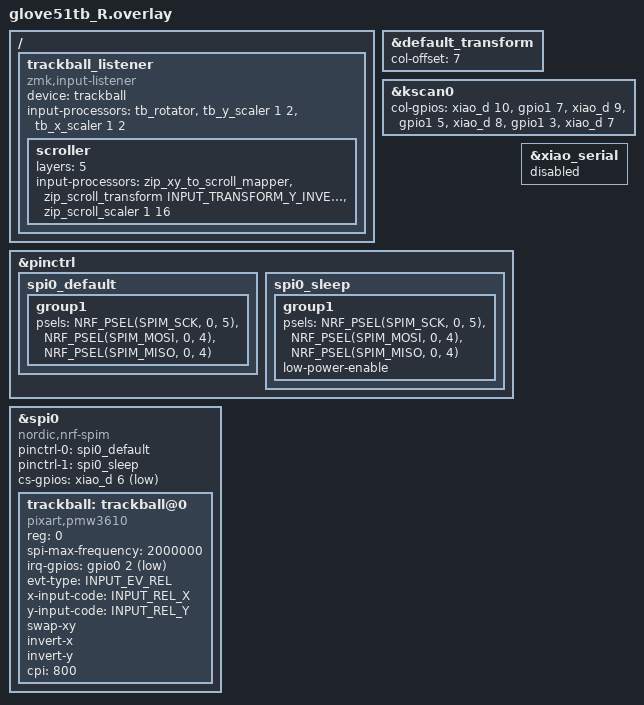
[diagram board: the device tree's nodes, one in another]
#include "glove51tb.dtsi"
#include <zephyr/dt-bindings/input/input-event-codes.h>
#include <dt-bindings/zmk/input_transform.h>
#include <input/processors.dtsi>

&default_transform {
    col-offset = <7>;
};

&kscan0 {
        col-gpios
            = <&xiao_d 10 GPIO_ACTIVE_HIGH>
            , <&gpio1 7  GPIO_ACTIVE_HIGH>
            , <&xiao_d 9  GPIO_ACTIVE_HIGH>
            , <&gpio1 5  GPIO_ACTIVE_HIGH>
            , <&xiao_d 8  GPIO_ACTIVE_HIGH>
            , <&gpio1 3  GPIO_ACTIVE_HIGH>
            , <&xiao_d 7  GPIO_ACTIVE_HIGH>
            ;
};

/ {
    trackball_listener {
        status = "okay";
        compatible = "zmk,input-listener";
        device = <&trackball>;
        input-processors = <&tb_rotator &tb_y_scaler 1 2 &tb_x_scaler 1 2>;

        scroller {
            layers = <5>;                                      // スクロールレイヤー
            input-processors = <
                &zip_xy_to_scroll_mapper                       // XY移動でスクロール
                &zip_scroll_transform INPUT_TRANSFORM_Y_INVERT // スクロールのY軸を反転
                &zip_scroll_scaler 1 16                        // スクロール感度調整
            >;
        };
    };
};

&pinctrl {
    spi0_default: spi0_default {
        group1 {
            psels = <NRF_PSEL(SPIM_SCK, 0, 5)>,
                <NRF_PSEL(SPIM_MOSI, 0, 4)>,
                <NRF_PSEL(SPIM_MISO, 0, 4)>;
        };
    };

    spi0_sleep: spi0_sleep {
        group1 {
            psels = <NRF_PSEL(SPIM_SCK, 0, 5)>,
                <NRF_PSEL(SPIM_MOSI, 0, 4)>,
                <NRF_PSEL(SPIM_MISO, 0, 4)>;
            low-power-enable;
        };
    };
};

&xiao_serial { status = "disabled"; };

&spi0 {
    status = "okay";
    compatible = "nordic,nrf-spim";
    pinctrl-0 = <&spi0_default>;
    pinctrl-1 = <&spi0_sleep>;
    pinctrl-names = "default", "sleep";
    cs-gpios = <&xiao_d 6 GPIO_ACTIVE_LOW>;

    trackball: trackball@0 {
        status = "okay";
        compatible = "pixart,pmw3610";
        reg = <0>;
        spi-max-frequency = <2000000>;
        irq-gpios = <&gpio0 2 (GPIO_ACTIVE_LOW | GPIO_PULL_UP)>;
        evt-type = <INPUT_EV_REL>;
        x-input-code = <INPUT_REL_X>;
        y-input-code = <INPUT_REL_Y>;
        swap-xy;      // マウス操作のX軸とY軸を入れ替え
        invert-x;     // マウス操作のX軸を反転
        invert-y;     // マウス操作のY軸を反転
        cpi = <800>;  // マウス感度
    };
};
